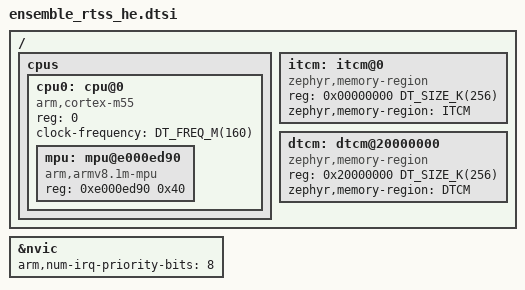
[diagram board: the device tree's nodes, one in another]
/*
 * Copyright (c) 2025 Alif Semiconductor
 *
 * SPDX-License-Identifier: Apache-2.0
 */

#include <arm/armv8.1-m.dtsi>
#include <freq.h>

/ {
	cpus {
		#address-cells = <1>;
		#size-cells = <0>;

		cpu0: cpu@0 {
			device_type = "cpu";
			compatible = "arm,cortex-m55";
			reg = <0>;
			clock-frequency = <DT_FREQ_M(160)>;
			#address-cells = <1>;
			#size-cells = <1>;

			mpu: mpu@e000ed90 {
				compatible = "arm,armv8.1m-mpu";
				reg = <0xe000ed90 0x40>;
			};
		};
	};

	itcm: itcm@0 {
		compatible = "zephyr,memory-region", "arm,itcm";
		reg = <0x00000000 DT_SIZE_K(256)>;
		zephyr,memory-region = "ITCM";
	};

	dtcm: dtcm@20000000 {
		compatible = "zephyr,memory-region", "arm,dtcm";
		reg = <0x20000000 DT_SIZE_K(256)>;
		zephyr,memory-region = "DTCM";
	};
};

&nvic {
	arm,num-irq-priority-bits = <8>;
};
